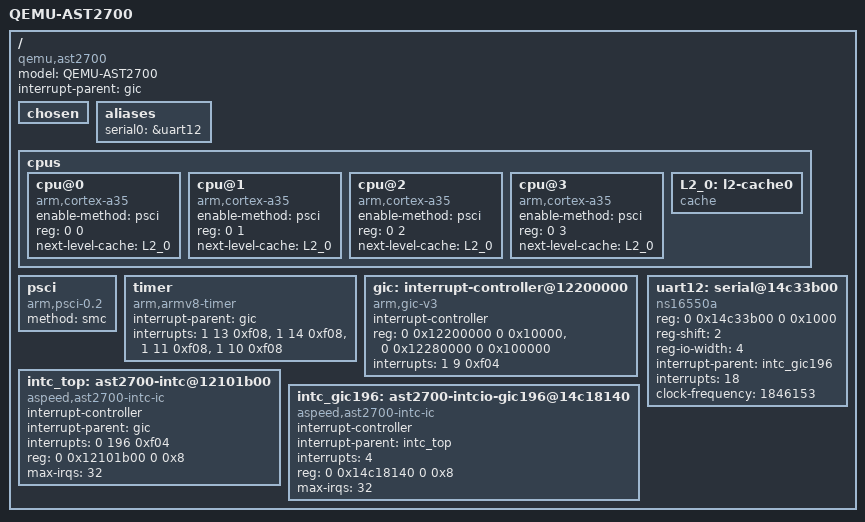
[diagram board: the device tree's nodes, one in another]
// SPDX-License-Identifier: Apache-2.0
/*
 * Copyright (c) 2025 Xing Loong <xing.xl.loong@gmail.com>
 * QEMU-AST2700-ARMv8 (Cortex-A35 x 4)
 * only present the nodes for a Minimum-System @ AST2700-A1
 */

/dts-v1/;

#include "memory.dtsi"

/ {
	model = "QEMU-AST2700";
	compatible = "qemu,ast2700";
	interrupt-parent = <&gic>;
	#address-cells = <2>;
	#size-cells = <2>;

	chosen { };

	aliases {
		serial0 = &uart12;
	};

	cpus {
		#address-cells = <2>;
		#size-cells = <0>;

		cpu@0 {
			device_type = "cpu";
			compatible = "arm,cortex-a35";
			enable-method = "psci";
			reg = <0 0>;
			next-level-cache = <&L2_0>;
		};

		cpu@1 {
			device_type = "cpu";
			compatible = "arm,cortex-a35";
			enable-method = "psci";
			reg = <0 1>;
			next-level-cache = <&L2_0>;
		};

		cpu@2 {
			device_type = "cpu";
			compatible = "arm,cortex-a35";
			enable-method = "psci";
			reg = <0 2>;
			next-level-cache = <&L2_0>;
		};

		cpu@3 {
			device_type = "cpu";
			compatible = "arm,cortex-a35";
			enable-method = "psci";
			reg = <0 3>;
			next-level-cache = <&L2_0>;
		};

		L2_0: l2-cache0 {
			compatible = "cache";
		};
	};

	psci {
		compatible = "arm,psci-0.2";
		method = "smc";
	};

	timer {
		compatible = "arm,armv8-timer";
		interrupt-parent = <&gic>;
		interrupts = <1 13 0xf08>,
				 <1 14 0xf08>,
				 <1 11 0xf08>,
				 <1 10 0xf08>;
	};

	gic: interrupt-controller@12200000 {
		compatible = "arm,gic-v3";
		#interrupt-cells = <3>;
		#size-cells = <0x02>;
		#address-cells = <0x02>;
		interrupt-controller;
		reg = <0 0x12200000 0 0x10000>,
			  <0 0x12280000 0 0x100000>;

		interrupts = <1 9 0xf04>;
	};

	/*
	 * AST2700-A1 two-level interrupt controller hierarchy:
	 * UART12 -> INTCIO GICINT196 bit18 -> INTC GICINT192_201 bit4 -> GIC SPI 196
	 */

	/* Top-level INTC: GICINT192_201 aggregate controller */
	intc_top: ast2700-intc@12101b00 {
		compatible = "aspeed,ast2700-intc-ic";
		interrupt-controller;
		#interrupt-cells = <1>;
		interrupt-parent = <&gic>;
		interrupts = <0 196 0xf04>;
		reg = <0 0x12101b00 0 0x8>;
		max-irqs = <32>;
	};

	/* INTCIO: per-GICINT196 controller (UART group) */
	intc_gic196: ast2700-intcio-gic196@14c18140 {
		compatible = "aspeed,ast2700-intc-ic";
		interrupt-controller;
		#interrupt-cells = <1>;
		interrupt-parent = <&intc_top>;
		interrupts = <4>;
		reg = <0 0x14c18140 0 0x8>;
		max-irqs = <32>;
	};

	uart12: serial@14c33b00 {
		compatible = "ns16550a";
		reg = <0 0x14c33b00 0 0x1000>;
		reg-shift = <2>;
		reg-io-width = <4>;
		interrupt-parent = <&intc_gic196>;
		interrupts = <18>;
		clock-frequency = <1846153>;
	};
};
